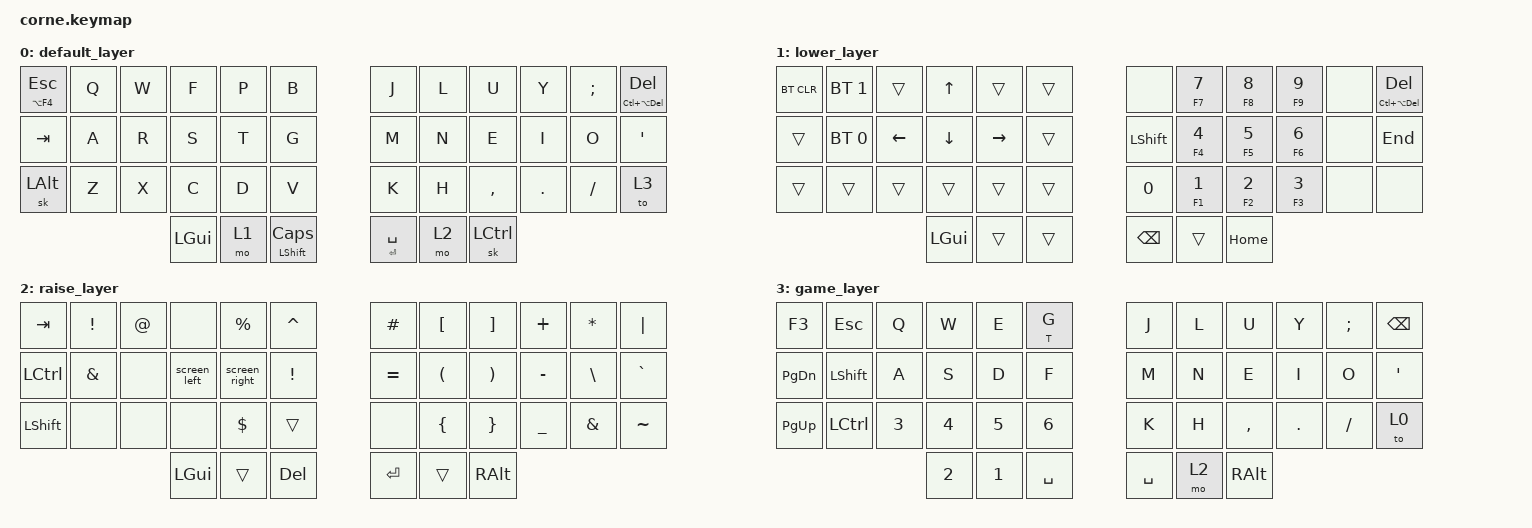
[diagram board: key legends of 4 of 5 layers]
/*
 * Copyright (c) 2020 The ZMK Contributors
 *
 * SPDX-License-Identifier: MIT
 */

#include <behaviors.dtsi>
#include <dt-bindings/zmk/keys.h>
#include <dt-bindings/zmk/bt.h>
#include <dt-bindings/zmk/mouse.h>
 
/{
    conditional_layers {
        compatible = "zmk,conditional-layers";
        tri_layer {
            if-layers = <1 2>;
            then-layer = <4>;
        };
    };
};

/{
    macros {
        screen_left: screen_left {
            label = "SCREEN_LEFT";
            compatible = "zmk,behavior-macro";
            #binding-cells = <0>;
            bindings
                = <&macro_press &kp LGUI &kp LCTRL>
                , <&macro_tap &kp LEFT>
                , <&macro_release &kp LGUI &kp LCTRL>
                ;
        };
        screen_right: screen_right {
            label = "SCREEN_RIGHT";
            compatible = "zmk,behavior-macro";
            #binding-cells = <0>;
            bindings
                = <&macro_press &kp LGUI &kp LCTRL>
                , <&macro_tap &kp RIGHT>
                , <&macro_release &kp LGUI &kp LCTRL>
                ;
        };
    };
};

/ {
        keymap {
                compatible = "zmk,keymap";

                default_layer {
                        bindings = <

   &mt LA(F4) ESC           &kp Q     &kp W     &kp F   &kp P &kp B                 &kp J &kp L  &kp U     &kp Y   &kp SEMI &mt LC(LA(DEL)) DEL
   &kp TAB                  &kp A     &kp R     &kp S   &kp T &kp G                 &kp M &kp N  &kp E     &kp I   &kp O    &kp SQT
   &sk LALT                 &kp Z     &kp X     &kp C   &kp D &kp V                 &kp K &kp H  &kp COMMA &kp DOT &kp FSLH &to 3
                                &kp LGUI    &mo 1   &mt LSHFT CAPS              &mt RET SPACE &mo 2 &sk LCTRL
                        
                        >;
                };
                lower_layer {
                        bindings = <

   &bt BT_CLR   &bt BT_SEL 1 &trans       &kp UP        &trans      &trans                &none       &mt F7 N7   &mt F8 N8   &mt F9 N9   &none &mt LC(LA(DEL)) DEL
   &trans       &bt BT_SEL 0 &kp LEFT     &kp DOWN      &kp RIGHT   &trans                &kp LSHFT   &mt F4 N4   &mt F5 N5   &mt F6 N6   &none &kp END
   &trans       &trans       &trans       &trans        &trans      &trans                &kp N0      &mt F1 N1   &mt F2 N2   &mt F3 N3   &none &none
                          	              &kp LGUI      &trans      &trans                &kp BSPC    &trans      &kp HOME

                        >;
                };

                raise_layer {
                        bindings = <

   &kp TAB      &kp EXCL    &kp AT &none        &kp PRCNT       &kp CARET                       &kp HASH    &kp LBKT  &kp RBKT  &kp PLUS    &kp STAR    &kp PIPE
   &kp LCTRL    &kp AMPS    &none &screen_left  &screen_right   &kp EXCL                        &kp EQUAL   &kp LPAR  &kp RPAR  &kp MINUS   &kp BSLH    &kp GRAVE
   &kp LSHFT    &none       &none &none         &kp DLLR        &trans                          &none       &kp LBRC  &kp RBRC  &kp UNDER   &kp AMPS    &kp TILDE
                    	    &kp LGUI            &trans          &kp DEL                         &kp RET     &trans    &kp RALT
                        
                        >;
                };

                game_layer {
                        bindings = <
   &kp F3       &kp ESC         &kp Q   &kp W   &kp E   &mt T G       &kp J   &kp L  &kp U     &kp Y   &kp SEMI &kp BSPC
   &kp PG_DN    &kp LSHFT       &kp A   &kp S   &kp D   &kp F         &kp M   &kp N  &kp E     &kp I   &kp O    &kp SQT
   &kp PG_UP    &kp LCTRL       &kp N3  &kp N4  &kp N5  &kp N6        &kp K   &kp H  &kp COMMA &kp DOT &kp FSLH &to 0
                                &kp N2  &kp N1  &kp SPACE             &kp SPACE &mo 2 &kp RALT
                        
                        >;
                };

                mouse_layer {
                        bindings = <
   &trans      &trans &kp LG(LBKT)      &mmv MOVE_UP        &kp LG(RBKT)        &trans                &none       &mwh SCROLL_UP    &none       &none       &none &none
   &trans      &trans &mmv MOVE_LEFT    &mmv MOVE_DOWN      &mmv MOVE_RIGHT     &trans                &none       &mkp LCLK         &mkp RCLK   &mkp MCLK   &none &none
   &trans      &trans &trans            &trans              &trans              &trans                &none       &mwh SCROLL_DOWN  &none       &none       &none
                          	             &kp LGUI      &trans      &none                &none     &trans      &none
                        
                        >;
                };

        };
};
